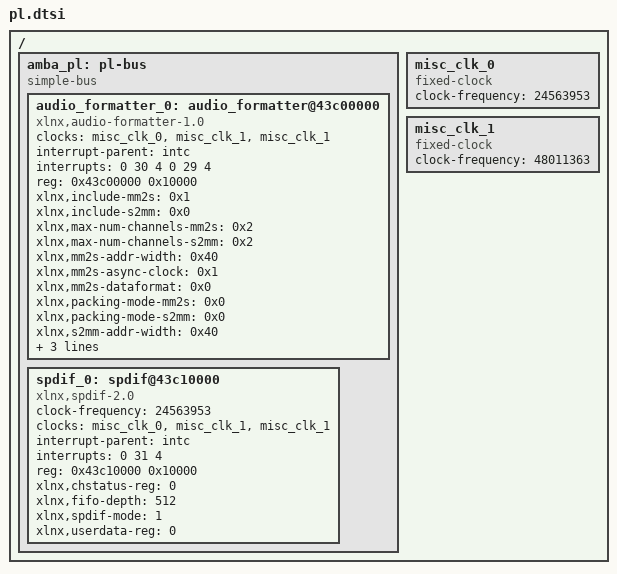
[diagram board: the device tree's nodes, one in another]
/*
 * CAUTION: This file is automatically generated by Xilinx.
 * Version: XSCT 
 * Today is: Sun Oct 19 18:21:45 2025
 */


/ {
	amba_pl: pl-bus {
		#address-cells = <1>;
		#size-cells = <1>;
		compatible = "simple-bus";
		ranges ;
		audio_formatter_0: audio_formatter@43c00000 {
			clock-names = "aud_mclk", "m_axis_mm2s_aclk", "s_axi_lite_aclk";
			clocks = <&misc_clk_0>, <&misc_clk_1>, <&misc_clk_1>;
			compatible = "xlnx,audio-formatter-1.0", "xlnx,audio-formatter-1.0";
			interrupt-names = "irq_mm2s", "irq_s2mm";
			interrupt-parent = <&intc>;
			interrupts = <0 30 4 0 29 4>;
			reg = <0x43c00000 0x10000>;
			xlnx,include-mm2s = <0x1>;
			xlnx,include-s2mm = <0x0>;
			xlnx,max-num-channels-mm2s = <0x2>;
			xlnx,max-num-channels-s2mm = <0x2>;
			xlnx,mm2s-addr-width = <0x40>;
			xlnx,mm2s-async-clock = <0x1>;
			xlnx,mm2s-dataformat = <0x0>;
			xlnx,packing-mode-mm2s = <0x0>;
			xlnx,packing-mode-s2mm = <0x0>;
			xlnx,s2mm-addr-width = <0x40>;
			xlnx,s2mm-async-clock = <0x1>;
			xlnx,s2mm-dataformat = <0x1>;
			xlnx,tx = <&spdif_0>;
		};
		spdif_0: spdif@43c10000 {
			clock-frequency = <24563953>;
			clock-names = "aud_clk_i", "s_axi_aclk", "s_axis_aclk";
			clocks = <&misc_clk_0>, <&misc_clk_1>, <&misc_clk_1>;
			compatible = "xlnx,spdif-2.0", "xlnx,spdif-2.0";
			interrupt-names = "spdif_interrupt";
			interrupt-parent = <&intc>;
			interrupts = <0 31 4>;
			reg = <0x43c10000 0x10000>;
			xlnx,chstatus-reg = <0>;
			xlnx,fifo-depth = <512>;
			xlnx,spdif-mode = <1>;
			xlnx,userdata-reg = <0>;
		};
	};
	misc_clk_0: misc_clk_0 {
		#clock-cells = <0>;
		clock-frequency = <24563953>;
		compatible = "fixed-clock";
	};
	misc_clk_1: misc_clk_1 {
		#clock-cells = <0>;
		clock-frequency = <48011363>;
		compatible = "fixed-clock";
	};
};
